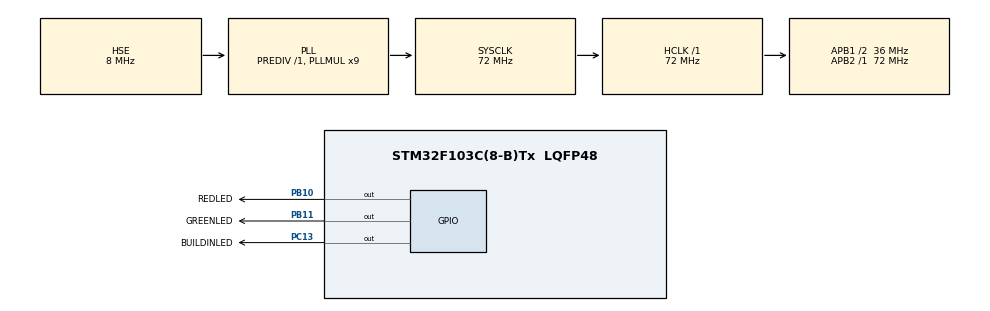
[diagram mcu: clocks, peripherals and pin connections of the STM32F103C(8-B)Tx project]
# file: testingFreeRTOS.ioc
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FREERTOS.BinarySemaphores01=LedGreenBSemaphore,Dynamic,NULL
FREERTOS.INCLUDE_vTaskDelayUntil=1
FREERTOS.Tasks01=LedRedTask,-2,128,vLedRedTask,Default,NULL,Dynamic,NULL,NULL;LedGreenTask,0,128,vLedGreenTask,Default,NULL,Dynamic,NULL,NULL;IdleTask,-3,128,vIdleTask,Default,NULL,Dynamic,NULL,NULL
FREERTOS.configQUEUE_REGISTRY_SIZE=5
FREERTOS.configUSE_NEWLIB_REENTRANT=1
Mcu.Family=STM32F1
Mcu.Name=STM32F103C(8-B)Tx
Mcu.Package=LQFP48
NVIC.PriorityGroup=NVIC_PRIORITYGROUP_4
NVIC.TIM1_UP_IRQn=true\:15\:0\:false\:false\:true\:false\:false\:true\:true
NVIC.TimeBase=TIM1_UP_IRQn
NVIC.TimeBaseIP=TIM1
PA13.Mode=Trace_Asynchronous_SW
PA13.Signal=SYS_JTMS-SWDIO
PA14.Mode=Trace_Asynchronous_SW
PA14.Signal=SYS_JTCK-SWCLK
PB10.GPIO_Label=REDLED
PB10.GPIO_PuPd=GPIO_PULLUP
PB10.PinState=GPIO_PIN_RESET
PB10.Signal=GPIO_Output
PB11.GPIO_Label=GREENLED
PB11.GPIO_PuPd=GPIO_PULLUP
PB11.Signal=GPIO_Output
PB3.Mode=Trace_Asynchronous_SW
PB3.Signal=SYS_JTDO-TRACESWO
PC13-TAMPER-RTC.GPIO_Label=BUILDINLED
PC13-TAMPER-RTC.Signal=GPIO_Output
PD0-OSC_IN.Mode=HSE-External-Oscillator
PD0-OSC_IN.Signal=RCC_OSC_IN
PD1-OSC_OUT.Mode=HSE-External-Oscillator
PD1-OSC_OUT.Signal=RCC_OSC_OUT
ProjectManager.HeapSize=0x200
ProjectManager.StackSize=0x400
ProjectManager.TargetToolchain=STM32CubeIDE
RCC.ADCPresc=RCC_ADCPCLK2_DIV6
RCC.AHBFreq_Value=72000000
RCC.APB1CLKDivider=RCC_HCLK_DIV2
RCC.APB1Freq_Value=36000000
RCC.APB1TimFreq_Value=72000000
RCC.APB2Freq_Value=72000000
RCC.APB2TimFreq_Value=72000000
RCC.HCLKFreq_Value=72000000
RCC.PLLMUL=RCC_PLL_MUL9
RCC.PLLSourceVirtual=RCC_PLLSOURCE_HSE
RCC.SYSCLKFreq_VALUE=72000000
RCC.SYSCLKSource=RCC_SYSCLKSOURCE_PLLCLK
RCC.USBFreq_Value=72000000
VP_FREERTOS_VS_CMSIS_V1.Mode=CMSIS_V1
VP_SYS_VS_tim1.Mode=TIM1
board=custom

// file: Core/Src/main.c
/* USER CODE BEGIN Header */
/**
  ******************************************************************************
  * @file           : main.c
  * @brief          : Main program body
  ******************************************************************************
  * @attention
  *
  * Copyright (c) 2022 STMicroelectronics.
  * All rights reserved.
  *
  * This software is licensed under terms that can be found in the LICENSE file
  * in the root directory of this software component.
  * If no LICENSE file comes with this software, it is provided AS-IS.
  *
  ******************************************************************************
  */
/* USER CODE END Header */
#include "main.h"
#include "cmsis_os.h"

osThreadId LedRedTaskHandle;
osThreadId LedGreenTaskHandle;
osThreadId IdleTaskHandle;
osSemaphoreId LedGreenBSemaphoreHandle;
/* USER CODE BEGIN PV */
volatile uint16_t event_delay_counter;
/* USER CODE END PV */

void SystemClock_Config(void);
static void MX_GPIO_Init(void);
void vLedRedTask(void const * argument);
void vLedGreenTask(void const * argument);
void vIdleTask(void const * argument);

int main(void)
{

  /* MCU Configuration--------------------------------------------------------*/

  /* Reset of all peripherals, Initializes the Flash interface and the Systick. */
  HAL_Init();

  /* Configure the system clock */
  SystemClock_Config();

  /* Initialize all configured peripherals */
  MX_GPIO_Init();

  /* Create the semaphores(s) */
  /* definition and creation of LedGreenBSemaphore */
  osSemaphoreDef(LedGreenBSemaphore);
  LedGreenBSemaphoreHandle = osSemaphoreCreate(osSemaphore(LedGreenBSemaphore), 1);

  /* Create the thread(s) */
  /* definition and creation of LedRedTask */
  osThreadDef(LedRedTask, vLedRedTask, osPriorityLow, 0, 128);
  LedRedTaskHandle = osThreadCreate(osThread(LedRedTask), NULL);

  /* definition and creation of LedGreenTask */
  osThreadDef(LedGreenTask, vLedGreenTask, osPriorityNormal, 0, 128);
  LedGreenTaskHandle = osThreadCreate(osThread(LedGreenTask), NULL);

  /* definition and creation of IdleTask */
  osThreadDef(IdleTask, vIdleTask, osPriorityIdle, 0, 128);
  IdleTaskHandle = osThreadCreate(osThread(IdleTask), NULL);

  /* Start scheduler */
  osKernelStart();

  /* We should never get here as control is now taken by the scheduler */
  /* Infinite loop */
  while (1)
  {

  }
}

void SystemClock_Config(void)
{
  RCC_OscInitTypeDef RCC_OscInitStruct = {0};
  RCC_ClkInitTypeDef RCC_ClkInitStruct = {0};

  /** Initializes the RCC Oscillators according to the specified parameters
  * in the RCC_OscInitTypeDef structure.
  */
  RCC_OscInitStruct.OscillatorType = RCC_OSCILLATORTYPE_HSE;
  RCC_OscInitStruct.HSEState = RCC_HSE_ON;
  RCC_OscInitStruct.HSEPredivValue = RCC_HSE_PREDIV_DIV1;
  RCC_OscInitStruct.HSIState = RCC_HSI_ON;
  RCC_OscInitStruct.PLL.PLLState = RCC_PLL_ON;
  RCC_OscInitStruct.PLL.PLLSource = RCC_PLLSOURCE_HSE;
  RCC_OscInitStruct.PLL.PLLMUL = RCC_PLL_MUL9;
  if (HAL_RCC_OscConfig(&RCC_OscInitStruct) != HAL_OK)
  {
    Error_Handler();
  }

  /** Initializes the CPU, AHB and APB buses clocks
  */
  RCC_ClkInitStruct.ClockType = RCC_CLOCKTYPE_HCLK|RCC_CLOCKTYPE_SYSCLK
                              |RCC_CLOCKTYPE_PCLK1|RCC_CLOCKTYPE_PCLK2;
  RCC_ClkInitStruct.SYSCLKSource = RCC_SYSCLKSOURCE_PLLCLK;
  RCC_ClkInitStruct.AHBCLKDivider = RCC_SYSCLK_DIV1;
  RCC_ClkInitStruct.APB1CLKDivider = RCC_HCLK_DIV2;
  RCC_ClkInitStruct.APB2CLKDivider = RCC_HCLK_DIV1;

  if (HAL_RCC_ClockConfig(&RCC_ClkInitStruct, FLASH_LATENCY_2) != HAL_OK)
  {
    Error_Handler();
  }
}

static void MX_GPIO_Init(void)
{
  GPIO_InitTypeDef GPIO_InitStruct = {0};

  /* GPIO Ports Clock Enable */
  __HAL_RCC_GPIOC_CLK_ENABLE();
  __HAL_RCC_GPIOD_CLK_ENABLE();
  __HAL_RCC_GPIOB_CLK_ENABLE();
  __HAL_RCC_GPIOA_CLK_ENABLE();

  /*Configure GPIO pin Output Level */
  HAL_GPIO_WritePin(BUILDINLED_GPIO_Port, BUILDINLED_Pin, GPIO_PIN_RESET);

  /*Configure GPIO pin Output Level */
  HAL_GPIO_WritePin(GPIOB, REDLED_Pin|GREENLED_Pin, GPIO_PIN_RESET);

  /*Configure GPIO pin : BUILDINLED_Pin */
  GPIO_InitStruct.Pin = BUILDINLED_Pin;
  GPIO_InitStruct.Mode = GPIO_MODE_OUTPUT_PP;
  GPIO_InitStruct.Pull = GPIO_NOPULL;
  GPIO_InitStruct.Speed = GPIO_SPEED_FREQ_LOW;
  HAL_GPIO_Init(BUILDINLED_GPIO_Port, &GPIO_InitStruct);

  /*Configure GPIO pins : REDLED_Pin GREENLED_Pin */
  GPIO_InitStruct.Pin = REDLED_Pin|GREENLED_Pin;
  GPIO_InitStruct.Mode = GPIO_MODE_OUTPUT_PP;
  GPIO_InitStruct.Pull = GPIO_PULLUP;
  GPIO_InitStruct.Speed = GPIO_SPEED_FREQ_LOW;
  HAL_GPIO_Init(GPIOB, &GPIO_InitStruct);

}

void vLedRedTask(void const * argument)
{
  /* USER CODE BEGIN 5 */
  event_delay_counter = 0;

  for(;;)
  {
    HAL_GPIO_TogglePin(REDLED_GPIO_Port, REDLED_Pin);

    if(++event_delay_counter > GREENLED_TASK_DELAY)
    {
      event_delay_counter = 0;
      osSemaphoreRelease(LedGreenBSemaphoreHandle);
    }
    osDelay(REDLED_TOGGLE_DELAY_MS);
  }
  /* USER CODE END 5 */
}

void vLedGreenTask(void const * argument)
{
  /* USER CODE BEGIN vLedGreenTask */
  /* Infinite loop */
  for(;;)
  {
//    xSemaphoreTake()
    osSemaphoreWait(LedGreenBSemaphoreHandle, portMAX_DELAY);
    HAL_GPIO_TogglePin(GREENLED_GPIO_Port, GREENLED_Pin);
    for(int16_t i = 3000; i > 0; i --)
    {
    	for(int16_t j = i; j > 0; j--);
    }
//    osDelay(1);
  }
  /* USER CODE END vLedGreenTask */
}

void vIdleTask(void const * argument)
{
  /* USER CODE BEGIN vIdleTask */
  /* Infinite loop */
  for(;;)
  {
	HAL_GPIO_TogglePin(BUILDINLED_GPIO_Port, BUILDINLED_Pin);
    osDelay(BUILDINLED_TOGGLE_DELAY_MS);
  }
  /* USER CODE END vIdleTask */
}

void HAL_TIM_PeriodElapsedCallback(TIM_HandleTypeDef *htim)
{
  if (htim->Instance == TIM1) {
    HAL_IncTick();
  }
}

void Error_Handler(void)
{
  __disable_irq();
  while (1)
  {
  }
}
